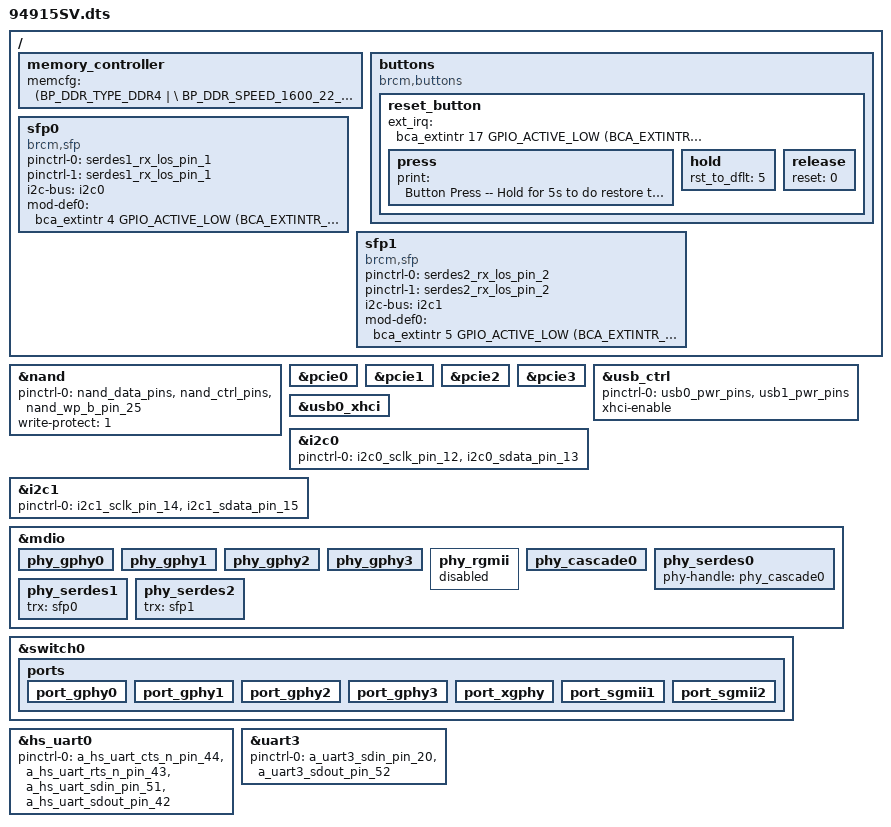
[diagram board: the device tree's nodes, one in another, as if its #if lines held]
#include "4912.dtsi"

/ {
	memory_controller {
		memcfg = <(BP_DDR_TYPE_DDR4           | \
			BP_DDR_SPEED_1600_22_22_22    | \
			BP_DDR_TOTAL_SIZE_4096MB      | \
			BP_DDR_DEVICE_WIDTH_8         | \
			BP_DDR_TOTAL_WIDTH_32BIT      | \
			BP_DDR_4912_DEFAULT          | \
			BP_DDR_CONFIG_DEBUG)>;
	};

	buttons {
		compatible = "brcm,buttons";
		reset_button {
			ext_irq = <&bca_extintr 17 GPIO_ACTIVE_LOW (BCA_EXTINTR_TYPE_LOW_LEVEL | BCA_EXTINTR_TYPE_SENSE_EDGE)>;
			press {
				print = "Button Press -- Hold for 5s to do restore to default";
			};
			hold {
				rst_to_dflt = <5>;
			};
			release {
				reset = <0>;
			};	
		};
	};

	sfp0: sfp0 {
		compatible = "brcm,sfp";
		pinctrl-names = "default", "rx-sd";
		pinctrl-0 = <&serdes1_rx_los_pin_1>;
		pinctrl-1 = <&serdes1_rx_los_pin_1>;
		
		i2c-bus = <&i2c0>;
		 mod-def0 = <&bca_extintr 4 GPIO_ACTIVE_LOW (BCA_EXTINTR_TYPE_BOTH_EDGE | BCA_EXTINTR_TYPE_SENSE_EDGE)>;
	};

	sfp1: sfp1 {
		compatible = "brcm,sfp";
		pinctrl-names = "default", "rx-sd";
		pinctrl-0 = <&serdes2_rx_los_pin_2>;
		pinctrl-1 = <&serdes2_rx_los_pin_2>;

		i2c-bus = <&i2c1>;
		mod-def0 = <&bca_extintr 5 GPIO_ACTIVE_LOW (BCA_EXTINTR_TYPE_BOTH_EDGE | BCA_EXTINTR_TYPE_SENSE_EDGE)>;
	};
};

&nand {
	pinctrl-0 = <&nand_data_pins &nand_ctrl_pins &nand_wp_b_pin_25>;
	write-protect = <1>;
	status = "okay";
};

#if defined(CONFIG_BCM_PCIE_HCD) || defined(CONFIG_BCM_PCIE_HCD_MODULE)
&pcie0 {
	status = "okay";
};
&pcie1 {
	status = "okay";
};
&pcie2 {
	status = "okay";
};
&pcie3 {
	status = "okay";
};
#endif //#if defined(CONFIG_BCM_PCIE_HCD) || defined(CONFIG_BCM_PCIE_HCD_MODULE)

&usb_ctrl {
	pinctrl-names = "default";
	pinctrl-0 = <&usb0_pwr_pins &usb1_pwr_pins>;
	status = "okay";
	xhci-enable;
};
&usb0_xhci {
	status = "okay";
};

&i2c0 {
	pinctrl-names = "default";
	pinctrl-0 = <&i2c0_sclk_pin_12 &i2c0_sdata_pin_13>;
	status = "okay";
};
&i2c1 {
	pinctrl-names = "default";
	pinctrl-0 = <&i2c1_sclk_pin_14 &i2c1_sdata_pin_15>;
	status = "okay";
};

&mdio {
    /* Port PHY mapping:
            port_gphy0 <----> phy_gphy0
            port_gphy1 <----> phy_gphy1
            port_gphy2 <----> phy_gphy2
            port_gphy3 <----> phy_gphy3
            port_xgphy <----> phy_serdes0   - phy_cascade0
            port_sgmii1 <---> phy_serdes1   - sfp0
            port_sgmii2 <---> phy_serdes2   - sfp1
     */
	phy_gphy0 {
		status = "okay";
	};

	phy_gphy1 {
		status = "okay";
	};

	phy_gphy2 {
		status = "okay";
	};

	phy_gphy3 {
		status = "okay";
	};

	phy_rgmii {
		status = "disabled";
	};

	phy_cascade0 {
		status = "okay";
	};

	phy_serdes0 {
		phy-handle = <&phy_cascade0>;
		status = "okay";
	};

	phy_serdes1 {
		trx = <&sfp0>;
		status = "okay";
	};

	phy_serdes2 {
		trx = <&sfp1>;
		status = "okay";
	};
};

&switch0 {
	ports {
		port_gphy0 {
			status = "okay";
		};

		port_gphy1 {
			status = "okay";
		};

		port_gphy2 {
			status = "okay";
		};

		port_gphy3 {
			status = "okay";
		};

		port_xgphy {
			status = "okay";
		};

		port_sgmii1 {
			status = "okay";
		};

		port_sgmii2 {
			status = "okay";
		};
	};
};
&hs_uart0 {
	pinctrl-names = "default";
	pinctrl-0 = <&a_hs_uart_cts_n_pin_44 &a_hs_uart_rts_n_pin_43 &a_hs_uart_sdin_pin_51 &a_hs_uart_sdout_pin_42 >;
	status = "okay";
};

&uart3 {
	pinctrl-names = "default";
	pinctrl-0 = <&a_uart3_sdin_pin_20 &a_uart3_sdout_pin_52 >;
	status = "okay";
};
